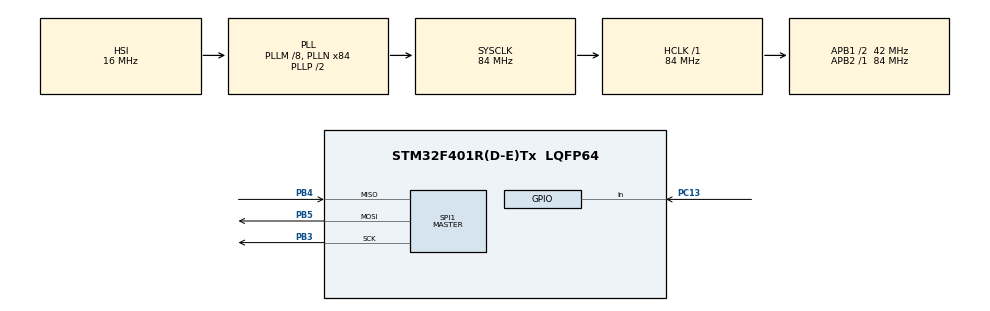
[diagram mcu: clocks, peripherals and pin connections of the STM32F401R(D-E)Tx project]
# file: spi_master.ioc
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Dma.Request0=SPI1_RX
Dma.Request1=SPI1_TX
Dma.SPI1_RX.0.Direction=DMA_PERIPH_TO_MEMORY
Dma.SPI1_RX.0.FIFOMode=DMA_FIFOMODE_DISABLE
Dma.SPI1_RX.0.Instance=DMA2_Stream0
Dma.SPI1_RX.0.MemDataAlignment=DMA_MDATAALIGN_BYTE
Dma.SPI1_RX.0.MemInc=DMA_MINC_ENABLE
Dma.SPI1_RX.0.Mode=DMA_NORMAL
Dma.SPI1_RX.0.PeriphDataAlignment=DMA_PDATAALIGN_BYTE
Dma.SPI1_RX.0.PeriphInc=DMA_PINC_DISABLE
Dma.SPI1_RX.0.Priority=DMA_PRIORITY_LOW
Dma.SPI1_TX.1.Direction=DMA_MEMORY_TO_PERIPH
Dma.SPI1_TX.1.FIFOMode=DMA_FIFOMODE_DISABLE
Dma.SPI1_TX.1.Instance=DMA2_Stream3
Dma.SPI1_TX.1.MemDataAlignment=DMA_MDATAALIGN_BYTE
Dma.SPI1_TX.1.MemInc=DMA_MINC_ENABLE
Dma.SPI1_TX.1.Mode=DMA_NORMAL
Dma.SPI1_TX.1.PeriphDataAlignment=DMA_PDATAALIGN_BYTE
Dma.SPI1_TX.1.PeriphInc=DMA_PINC_DISABLE
Dma.SPI1_TX.1.Priority=DMA_PRIORITY_LOW
Mcu.Family=STM32F4
Mcu.Name=STM32F401R(D-E)Tx
Mcu.Package=LQFP64
NVIC.DMA2_Stream0_IRQn=true\:0\:0\:false\:false\:true\:false\:true
NVIC.DMA2_Stream3_IRQn=true\:0\:0\:false\:false\:true\:false\:true
NVIC.PriorityGroup=NVIC_PRIORITYGROUP_4
PB3.Mode=Full_Duplex_Master
PB3.Signal=SPI1_SCK
PB4.Mode=Full_Duplex_Master
PB4.Signal=SPI1_MISO
PB5.Mode=Full_Duplex_Master
PB5.Signal=SPI1_MOSI
PC13-ANTI_TAMP.Signal=GPIO_Input
PH0\ -\ OSC_IN.Mode=HSE-External-Oscillator
PH0\ -\ OSC_IN.Signal=RCC_OSC_IN
PH1\ -\ OSC_OUT.Mode=HSE-External-Oscillator
PH1\ -\ OSC_OUT.Signal=RCC_OSC_OUT
ProjectManager.HeapSize=0x200
ProjectManager.StackSize=0x400
ProjectManager.TargetToolchain=STM32CubeIDE
RCC.48MHZClocksFreq_Value=42000000
RCC.AHBFreq_Value=84000000
RCC.APB1CLKDivider=RCC_HCLK_DIV2
RCC.APB1Freq_Value=42000000
RCC.APB1TimFreq_Value=84000000
RCC.APB2Freq_Value=84000000
RCC.APB2TimFreq_Value=84000000
RCC.CortexFreq_Value=84000000
RCC.HCLKFreq_Value=84000000
RCC.HSE_VALUE=8000000
RCC.HSI_VALUE=16000000
RCC.LSE_VALUE=32768
RCC.PLLM=8
RCC.PLLN=84
RCC.SYSCLKFreq_VALUE=84000000
RCC.SYSCLKSource=RCC_SYSCLKSOURCE_PLLCLK
RCC.VCOOutputFreq_Value=168000000
SPI1.BaudRatePrescaler=SPI_BAUDRATEPRESCALER_128
SPI1.CLKPhase=SPI_PHASE_1EDGE
SPI1.Direction=SPI_DIRECTION_2LINES
SPI1.Mode=SPI_MODE_MASTER
SPI1.VirtualType=VM_MASTER
board=custom

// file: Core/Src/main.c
/* USER CODE BEGIN Header */
/**
  ******************************************************************************
  * @file           : main.c
  * @brief          : Main program body
  ******************************************************************************
  * @attention
  *
  * <h2><center>&copy; Copyright (c) 2020 STMicroelectronics.
  * All rights reserved.</center></h2>
  *
  * This software component is licensed by ST under BSD 3-Clause license,
  * the "License"; You may not use this file except in compliance with the
  * License. You may obtain a copy of the License at:
  *                        opensource.org/licenses/BSD-3-Clause
  *
  ******************************************************************************
  */
/* USER CODE END Header */
#include "main.h"

/* USER CODE BEGIN Includes */
#include <string.h>
#include <stdbool.h>
/* USER CODE END Includes */

/* USER CODE BEGIN PD */
#define PIXELS_NUM  1000
/* USER CODE END PD */

SPI_HandleTypeDef hspi1;
DMA_HandleTypeDef hdma_spi1_rx;
DMA_HandleTypeDef hdma_spi1_tx;

/* USER CODE BEGIN PV */
uint8_t transmitBuffer[PIXELS_NUM*24];
uint8_t rxBuffer[5];
/* USER CODE END PV */

void SystemClock_Config(void);
static void MX_GPIO_Init(void);
static void MX_DMA_Init(void);
static void MX_SPI1_Init(void);

int main(void)
{

  /* MCU Configuration--------------------------------------------------------*/

  /* Reset of all peripherals, Initializes the Flash interface and the Systick. */
  HAL_Init();

  /* Configure the system clock */
  SystemClock_Config();

  /* Initialize all configured peripherals */
  MX_GPIO_Init();
  MX_DMA_Init();
  MX_SPI1_Init();
  /* USER CODE BEGIN 2 */
  memset(transmitBuffer, 0xAA, PIXELS_NUM*24);
  /* USER CODE END 2 */

  /* Infinite loop */
  /* USER CODE BEGIN WHILE */
	while (1)
	{
		if (!HAL_GPIO_ReadPin(GPIOC, GPIO_PIN_13))
		{
			HAL_SPI_TransmitReceive_DMA(&hspi1, transmitBuffer, rxBuffer, 1);
			HAL_Delay(50);
//			HAL_SPI_Transmit_DMA(&hspi1, transmitBuffer, PIXELS_NUM*24);
//			HAL_Delay(3);
//			HAL_SPI_Transmit_DMA(&hspi1, transmitBuffer, PIXELS_NUM*24);
//			HAL_Delay(100);
		}
    /* USER CODE END WHILE */

	}
}

void SystemClock_Config(void)
{
  RCC_OscInitTypeDef RCC_OscInitStruct = {0};
  RCC_ClkInitTypeDef RCC_ClkInitStruct = {0};

  /** Configure the main internal regulator output voltage
  */
  __HAL_RCC_PWR_CLK_ENABLE();
  __HAL_PWR_VOLTAGESCALING_CONFIG(PWR_REGULATOR_VOLTAGE_SCALE2);
  /** Initializes the RCC Oscillators according to the specified parameters
  * in the RCC_OscInitTypeDef structure.
  */
  RCC_OscInitStruct.OscillatorType = RCC_OSCILLATORTYPE_HSI;
  RCC_OscInitStruct.HSIState = RCC_HSI_ON;
  RCC_OscInitStruct.HSICalibrationValue = RCC_HSICALIBRATION_DEFAULT;
  RCC_OscInitStruct.PLL.PLLState = RCC_PLL_ON;
  RCC_OscInitStruct.PLL.PLLSource = RCC_PLLSOURCE_HSI;
  RCC_OscInitStruct.PLL.PLLM = 8;
  RCC_OscInitStruct.PLL.PLLN = 84;
  RCC_OscInitStruct.PLL.PLLP = RCC_PLLP_DIV2;
  RCC_OscInitStruct.PLL.PLLQ = 4;
  if (HAL_RCC_OscConfig(&RCC_OscInitStruct) != HAL_OK)
  {
    Error_Handler();
  }
  /** Initializes the CPU, AHB and APB buses clocks
  */
  RCC_ClkInitStruct.ClockType = RCC_CLOCKTYPE_HCLK|RCC_CLOCKTYPE_SYSCLK
                              |RCC_CLOCKTYPE_PCLK1|RCC_CLOCKTYPE_PCLK2;
  RCC_ClkInitStruct.SYSCLKSource = RCC_SYSCLKSOURCE_PLLCLK;
  RCC_ClkInitStruct.AHBCLKDivider = RCC_SYSCLK_DIV1;
  RCC_ClkInitStruct.APB1CLKDivider = RCC_HCLK_DIV2;
  RCC_ClkInitStruct.APB2CLKDivider = RCC_HCLK_DIV1;

  if (HAL_RCC_ClockConfig(&RCC_ClkInitStruct, FLASH_LATENCY_2) != HAL_OK)
  {
    Error_Handler();
  }
}

static void MX_SPI1_Init(void)
{

  /* SPI1 parameter configuration*/
  hspi1.Instance = SPI1;
  hspi1.Init.Mode = SPI_MODE_MASTER;
  hspi1.Init.Direction = SPI_DIRECTION_2LINES;
  hspi1.Init.DataSize = SPI_DATASIZE_8BIT;
  hspi1.Init.CLKPolarity = SPI_POLARITY_LOW;
  hspi1.Init.CLKPhase = SPI_PHASE_1EDGE;
  hspi1.Init.NSS = SPI_NSS_SOFT;
  hspi1.Init.BaudRatePrescaler = SPI_BAUDRATEPRESCALER_128;
  hspi1.Init.FirstBit = SPI_FIRSTBIT_MSB;
  hspi1.Init.TIMode = SPI_TIMODE_DISABLE;
  hspi1.Init.CRCCalculation = SPI_CRCCALCULATION_DISABLE;
  hspi1.Init.CRCPolynomial = 10;
  if (HAL_SPI_Init(&hspi1) != HAL_OK)
  {
    Error_Handler();
  }

}

static void MX_DMA_Init(void)
{

  /* DMA controller clock enable */
  __HAL_RCC_DMA2_CLK_ENABLE();

  /* DMA interrupt init */
  /* DMA2_Stream0_IRQn interrupt configuration */
  HAL_NVIC_SetPriority(DMA2_Stream0_IRQn, 0, 0);
  HAL_NVIC_EnableIRQ(DMA2_Stream0_IRQn);
  /* DMA2_Stream3_IRQn interrupt configuration */
  HAL_NVIC_SetPriority(DMA2_Stream3_IRQn, 0, 0);
  HAL_NVIC_EnableIRQ(DMA2_Stream3_IRQn);

}

static void MX_GPIO_Init(void)
{
  GPIO_InitTypeDef GPIO_InitStruct = {0};

  /* GPIO Ports Clock Enable */
  __HAL_RCC_GPIOC_CLK_ENABLE();
  __HAL_RCC_GPIOH_CLK_ENABLE();
  __HAL_RCC_GPIOB_CLK_ENABLE();

  /*Configure GPIO pin : PC13 */
  GPIO_InitStruct.Pin = GPIO_PIN_13;
  GPIO_InitStruct.Mode = GPIO_MODE_INPUT;
  GPIO_InitStruct.Pull = GPIO_NOPULL;
  HAL_GPIO_Init(GPIOC, &GPIO_InitStruct);

}

void Error_Handler(void)
{
}

/************************ (C) COPYRIGHT STMicroelectronics *****END OF FILE****/
